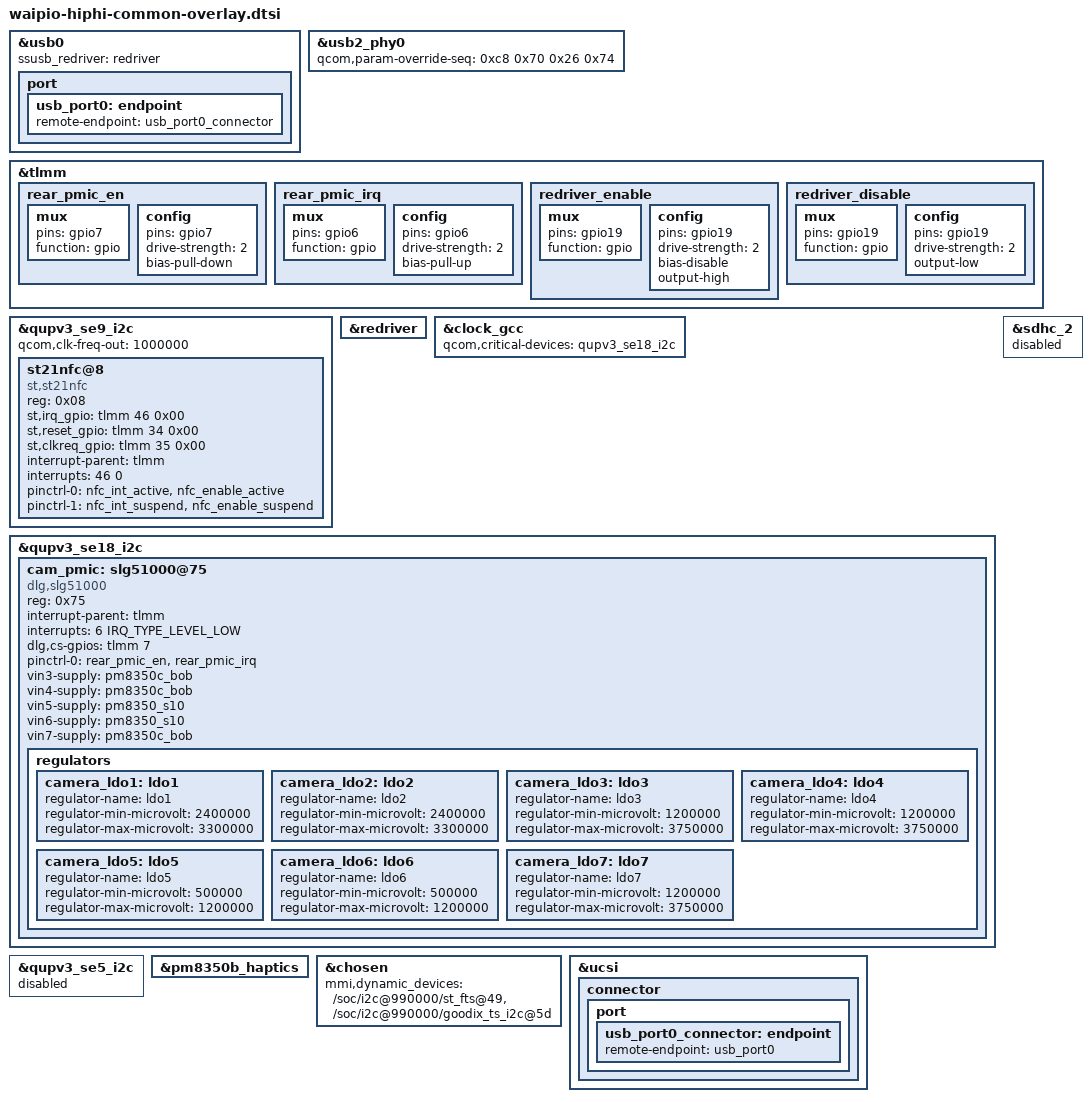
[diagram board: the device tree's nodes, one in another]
/* Copyright (c) 2021, The Linux Foundation. All rights reserved.
 *
 * This program is free software; you can redistribute it and/or modify
 * it under the terms of the GNU General Public License version 2 and
 * only version 2 as published by the Free Software Foundation.
 *
 * This program is distributed in the hope that it will be useful,
 * but WITHOUT ANY WARRANTY; without even the implied warranty of
 * MERCHANTABILITY or FITNESS FOR A PARTICULAR PURPOSE.  See the
 * GNU General Public License for more details.
 */

/*
   This base is original from "waipio-mtp-pm8008-overlay.dts"
*/
#include "waipio-moto-common-overlay-base.dtsi"

#include "waipio-moto-common-overlay.dtsi"
#include "waipio-moto-common-redriver.dtsi"
#include "waipio-hiphi-fingerprint.dtsi"
#include "waipio-hiphi-haptics-overlay.dtsi"
#include "waipio-moto-common-charger.dtsi"
#include "waipio-hiphic-thermal-overlay.dtsi"
#include "waipio-pm8010-spmi.dtsi"

&usb0 {
	ssusb_redriver = <&redriver>;

	port {
		usb_port0: endpoint {
			remote-endpoint = <&usb_port0_connector>;
		};
	};
};

&usb2_phy0 {
	qcom,param-override-seq =
		<0xc8 0x70
		0x26 0x74>;
};

&tlmm {
	rear_pmic_en: rear_pmic_en {
		mux {
			pins = "gpio7";
			function = "gpio";
		};

		config {
			pins = "gpio7";
			drive-strength = <2>; /* 2 mA */
			bias-pull-down;
		};
	};

	rear_pmic_irq: rear_pmic_irq {
		mux {
			pins = "gpio6";
			function = "gpio";
		};

		config {
			pins = "gpio6";
			drive-strength = <2>; /* 2 mA */
			bias-pull-up;
		};
	};

	redriver_enable: redriver_enable {
		mux {
			pins = "gpio19";
			function = "gpio";
		};

		config {
			pins = "gpio19";
			drive-strength = <2>;
			bias-disable; /* NO PULL */
			output-high;
		};
	};
	redriver_disable: redriver_disable {
		mux {
			pins = "gpio19";
			function = "gpio";
		};

		config {
			pins = "gpio19";
			drive-strength = <2>;
			output-low;
		};
	};
};

&qupv3_se9_i2c {
	status = "ok";
	qcom,clk-freq-out = <1000000>;
	#address-cells = <1>;
	#size-cells = <0>;
	st21nfc@8 {
		compatible = "st,st21nfc";
		reg = <0x08>;
		st,irq_gpio = <&tlmm 46 0x00>;
		st,reset_gpio = <&tlmm 34 0x00>;
		st,clkreq_gpio = <&tlmm 35 0x00>;
		interrupt-parent = <&tlmm>;
		interrupts = <46 0>;
		interrupt-names = "nfc_irq";
		pinctrl-names = "nfc_active", "nfc_suspend";
		pinctrl-0 = <&nfc_int_active &nfc_enable_active>;
		pinctrl-1 = <&nfc_int_suspend &nfc_enable_suspend>;
	};
};

&redriver {
	status = "ok";
};

/*
 * Each QUP device that's a parent to PMIC must be listed as a critical device
 * to GCC.
 */
&clock_gcc {
	qcom,critical-devices = <&qupv3_se18_i2c>;
};

&qupv3_se18_i2c {
	status = "ok";

	cam_pmic: slg51000@75 {
		compatible = "dlg,slg51000";
		reg = <0x75>;

		interrupt-parent = <&tlmm>;
		interrupts = <6 IRQ_TYPE_LEVEL_LOW>;

		dlg,cs-gpios = <&tlmm 7 0>;

		pinctrl-names = "pmic_default";
		pinctrl-0 = <&rear_pmic_en &rear_pmic_irq>;

		vin3-supply = <&pm8350c_bob>;
		vin4-supply = <&pm8350c_bob>;
		vin5-supply = <&pm8350_s10>;
		vin6-supply = <&pm8350_s10>;
		vin7-supply = <&pm8350c_bob>;

		regulators {
			camera_ldo1: ldo1 {
				regulator-name = "ldo1";
				regulator-min-microvolt = <2400000>;
				regulator-max-microvolt = <3300000>;
			};

			camera_ldo2: ldo2 {
				regulator-name = "ldo2";
				regulator-min-microvolt = <2400000>;
				regulator-max-microvolt = <3300000>;
			};

			camera_ldo3: ldo3 {
				regulator-name = "ldo3";
				regulator-min-microvolt = <1200000>;
				regulator-max-microvolt = <3750000>;
			};

			camera_ldo4: ldo4 {
				regulator-name = "ldo4";
				regulator-min-microvolt = <1200000>;
				regulator-max-microvolt = <3750000>;
			};

			camera_ldo5: ldo5 {
				regulator-name = "ldo5";
				regulator-min-microvolt = <500000>;
				regulator-max-microvolt = <1200000>;
			};

			camera_ldo6: ldo6 {
				regulator-name = "ldo6";
				regulator-min-microvolt = <500000>;
				regulator-max-microvolt = <1200000>;
			};

			camera_ldo7: ldo7 {
				regulator-name = "ldo7";
				regulator-min-microvolt = <1200000>;
				regulator-max-microvolt = <3750000>;
			};
		};
	};
};

&qupv3_se5_i2c {
	status = "disabled";
};

&pm8350b_haptics {
	status = "ok";
};

&sdhc_2 {
	status = "disabled";
};

&chosen {
	mmi,dynamic_devices = "/soc/i2c@990000/st_fts@49", "/soc/i2c@990000/goodix_ts_i2c@5d";
};

&ucsi {
	connector {
		port {
			usb_port0_connector: endpoint {
				remote-endpoint = <&usb_port0>;
			};
		};
	};
};
